# pse84 register map
Vendor: Infineon Technologies; Series: PSE84; File version: 1.0
CPU: CM33 r0p1, little endian, MPU, FPU, VTOR, 3 interrupt priority bits
Registers are 32-bit, read-write, reset 0x0 unless marked. A register's access mark holds for its fields unless they carry their own. Offsets are from the block's base; [hi:lo] are bit positions; lines under a group give offsets from that group; {n}, {i} and the like mark numbered series; 'fields as' and 'values as' point back to an identical list.

## ACTRLR — Autonomnous Controller
Base 0x42ED0000
0x00 CTRL — control register
  [31] ENABLED — - 0: LPPASS IP disabled - 1: LPPASS IP enabled This field functions as the Global Enable for the LPPASS IP. This field must be set to gain read/write access to any other register in the LPPASS memory map. During initial IP release from reset (i.e. during POR), the LPPASS IP (along with its switched internal power domain) is disabled. After setting this bit, the LPPASS internal switched domain is powered up. The user must then wait for PWR_STATUS.SW_OK to assert. At this point, the user has read/write access to all LPPASS memory map registers. Clearing this field (i.e. disabling the LPPASS) can lead to status only clearing, or status and configuration clearing (see CFG.DISABLE_MODE).
0x04 CMD_RUN — run command register
  [0] RUN — Autonomous Controller Run Command Firmware should only write to this field when STATUS=STOPPED or PAUSED. When firmware sets this field, the Autonomous Controller starts running at the State pointed to by CMD_STATE. Hardware clears this field when the Autonomous Controller acknowledges the run command. If this field is set while STATUS=RUNNING, the Autonomous Controller will not respond to the command (beyond clearing the field). This register is reset whenever the following occurs: 1. The Autonomous Controller is disabled (clearing CTRL.ENABLED) 2. The LPPASS is configured for HS mode (STATUS.MODE=0) and the chip leaves an Active Mode.
0x08 CMD_STATE — state override register
  [5:0] STATE — Autonomous Controller Command State This field indicates where which AC State (0-63) the AC will execute instructions from when it receives a RUN or SINGLE_STEP command. Hardware updates this field whenever the AC transitions from RUNNING to STOPPED or PAUSED. When STOPPED or PAUSED, firmware can overrwrite this field to force the AC to execute from a specific STATE when triggered by a subsequent RUN or SINGLE_STEP command. This field must never be written to if STATUS=RUNNING. This register is reset whenever the following occurs: 1. The Autonomous Controller is disabled (clearing CTRL.ENABLED) 2. The LPPASS is configured for HS mode (STATUS.MODE=0) and the chip leaves an Active Mode.
{0x10+4i} FW_TR[{i}] (i=0..3) — firmware trigger
  [0] FW_TR — Firmware Trigger This field is used as a firmware trigger for the Autonomous Controller. The Autonomous Controller can be programmed to respond to the firmware trigger by programming a state with a condtion (COND) TR_LPPASS_IN*. Additionally, writing to this field will force the Autonomus Controller to wake from sleep. Hardware clears this bit when the Autonomous Controller acknowledges the trigger. This register is reset whenever the following occurs: 1. The Autonomous Controller is disabled (clearing CTRL.ENABLED) 2. The LPPASS is configured for HS mode (STATUS.MODE=0) and the chip leaves an Active Mode.
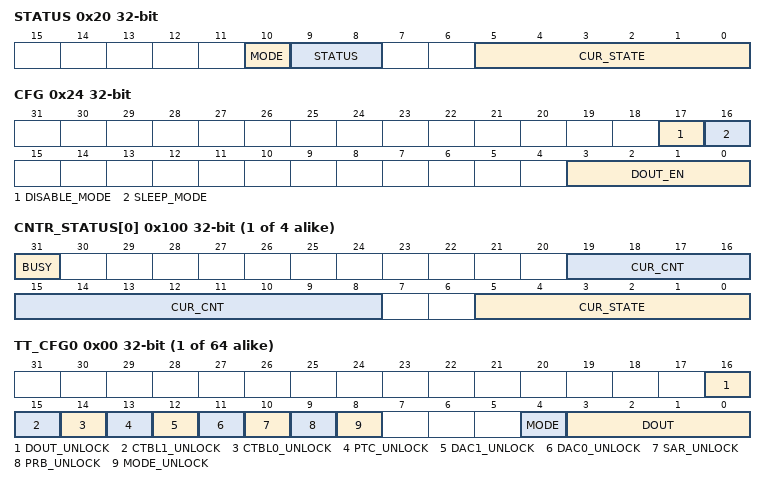
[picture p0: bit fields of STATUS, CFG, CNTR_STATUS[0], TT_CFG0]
0x20 STATUS ro
  [10] MODE — This field indicates the mode of the Autonomous Controller. The Autonmous Controller always resets to HS mode. This field is reset whenever the following occurs: 1. The Autonomous Controller is disabled (clearing CTRL.ENABLED) 2. The LPPASS is configured for HS mode (STATUS.MODE=0) and the chip leaves an Active Mode.
    0=HS (Autonomous Controller is in High Speed (HS) mode In this mode, the LPPASS IP is functional only in chip Active modes. The LPPASS IP is clocked from a peripheral source derived from clk_hf.); 1=LP (Autonomous Controller is Low Power (LP) mode In this mode, the LPPASS IP is functional in both chip Active and Deepsleep modes. The LPPASS IP is clocked from the internal LPOSC.)
  [9:8] STATUS — Autonomous Controller status
    0=STOPPED (Autonomous Controller is stopped); 1=RUNNING (Autonomous Controller is running); 2=PAUSED (Autonomous Controller is paused); 3=RSVD (N/A)
  [5:0] CUR_STATE — This register indicates the current state of the Autonomous Controller (valid values are 0-63).
0x24 CFG — config register (only accessible if CTRL.EN=0)
  [17] DISABLE_MODE — Autonomous Controller Disable Mode -0 : Keep the LPPASS switched digital supply powered when the AC is disabled ( i.e. CTRL.ENABLED=0). - 1: Power Down the LPPASS digital supply when AC is disabled. This has the following consequences to the LPPASS: 1. Digital leakage is reduced (i.e. all logic on the LPPASS switched supply is powered off). 2. All LPPASS configuration is lost (all registers are reset and SRAMs lose data).
  [16] SLEEP_MODE — Autonomous Controller Sleep Mode -0 : Keep the LPPASS switched digital supply powered when the AC is sleeping (i.e. AC state programmed to action (ACT)=WAIT_FOR, and condition (COND)=wakeup source). - 1: Power Down the LPPASS digital supply when AC is asleep (i.e. AC ACT=WAIT_FOR, AC_COND= wakeup source). This has the following consequences to the LPPASS: 1. Digital leakage is reduced (i.e. all logic on the LPPASS switched supply is powered off). 2. CTBLs, SAR FIRs, and the DACs loose all configuration (i.e. they must be re-programmed to be functional again). 3. The wakeup time is increased by 3us ( to account for the switched power domain coming up).
  [3:0] DOUT_EN — DOUT output enable. Bits in this field must be set prior to writing to TIMER_TABLE_STRUCT.TT_CF0_DOUT. -0 : DOUT[X] output disabled - 1: DOUT[X] output enabled
0x30 DEBUG_PAUSE — pause debug register
  [0] PAUSE — Pause Command Setting this field requests the Autonomous Controller (AC) to pause. This field is used for debug purposes only. The AC waits for the present state to complete before pausing. If the present state cannot complete (i.e. the ACT and COND are programmed improperly), the AC will not pause. This command must not be used when executing an AC sleep state (ACT=WAIT_FOR and COND=WAKE_*). When the AC is paused, all AC registerd conditions are cleared. Hardware clears this bit when the Autonomous Controller is paused. This command is ignored if STATUS.STATUS is PAUSED or STOP.
0x34 DEBUG_SINGLE_STEP — single step debug register
  [0] SINGLE_STEP — Single Step Command Setting this field requests the Autonomous Controller (AC) to execute the next AC state (pointed to by CMD_STATE.STATE) and pause after completing that state. This field is used for debug purposes only. If the state (pointed to by CMD_STATE.STATE) cannot complete (i.e. the ACT and COND are programmed improperly), the AC will not pause at the end of the single step command. This command must not be used when executing an AC sleep state (ACT=WAIT_FOR and COND=*_WAKE). When the AC is paused, all AC registerd conditions are cleared. Hardware clears this bit when the Autonomous Controller pauses after executing the single step command. This command is ignored if STATUS.STATUS is RUNNING.
0x38 PWR_STATUS ro — power status register
  [0] SW_OK — This field indicates the status of the LPPASS switched power domain. This status should be polled whenever CTRL.EN toggles from a 0 to 1. 0: switched domain is powered off. 1: switched domain is powered on.
{0x100+4i} CNTR_STATUS[{i}] (i=0..3) ro — Loop/Interval counter status register
  [31] BUSY — This field indicates if the counter is busy (i.e. count value is non-zero).
  [19:8] CUR_CNT — This field indicates the count value for the given counter.
  [5:0] CUR_STATE — This field indicates the assigned Autonomous Controller (AC) State of a counter. Valid numbers are 0-63.
{0x800+0x20*i} TTCFG[{i}] (i=0..63) group — Timer Table Structure (only accessible if CTRL.EN=0)
  0x00 TT_CFG0 — AC Table Configuration 0
    [16] DOUT_UNLOCK — DOUT Unlock 0: Lock: DOUT does NOT get updated 1: Unlock: DOUT does get updated
    [15] CTBL1_UNLOCK — See CTBL0_UNLOCK
    [14] CTBL0_UNLOCK — CTBL0 Unlock 0: Lock: CTBL0 fields: OPA1(0)_EN, OPA1(0)_GAIN, OPA1(0)_CFG do NOT get updated 1: Unlock: CTBL0 fields: OPA1(0)_EN, OPA1(0)_GAIN, OPA1(0)_CFG do get updated
    [13] PTC_UNLOCK — PTC Unlock 0: Lock: PTC fields: CMP1(0)_EN, CMP1(0)_CFG do NOT get updated 1: Unlock: PTC fields: CMP1(0)_EN, CMP1(0)_CFG do get updated
    [12] DAC1_UNLOCK — See DAC0_UNLOCK
    [11] DAC0_UNLOCK — DAC0 Unlock 0: Lock: DAC0 fields: EN does NOT get updated 1: Unlock: DAC0 fields: EN does get updated
    [10] SAR_UNLOCK — SAR Unlock 0: Lock: SAR fields: EN does NOT get updated 1: Unlock: SAR fields: EN does get updated
    [9] PRB_UNLOCK — PRB Unlock 0: Lock: PRB fields: VREF1(0)_VAL, VREF1(0)_FW_MODE do NOT get updated 1: Unlock: PRB fields: VREF1(0)_VAL, VREF1(0)_FW_MODE do get updated
    [8] MODE_UNLOCK — Mode Unlock 0: Lock: MODE does NOT get updated 1: Unlock: MODE does get updated
    [4] MODE — LPPASS Operating Mode 0: High Speed (HS) Operation - The PASS is clocked from CLK_HF directly (nominally 80MHz) and is only functional in chip Active mode (i.e. the IP is reset in chip Deepsleep and Hibernate) 1: Low Power (LP) Operation - The PASS is clocked from CLK_LPOSC (4MHz) and is functional in chip Active and Deepsleep mode (i.e. the IP is only reset in Hibernate)
    [3:0] DOUT — LPPASS data out generation (the corresponding bit in CFG.DOUT_EN must be set when using this field) The data out bus is driven directly to the GPIO HSIO interface. The HSIO interface must be programmed properly for the DOUT bus to be observed on the GPIO pins.
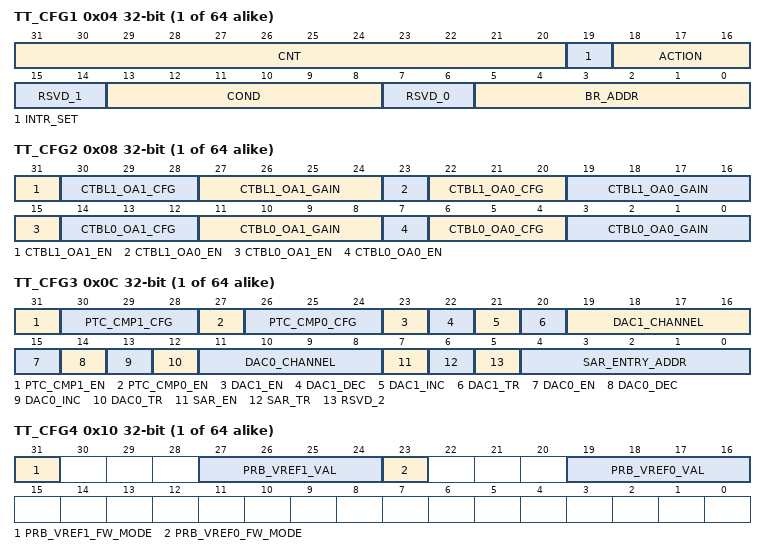
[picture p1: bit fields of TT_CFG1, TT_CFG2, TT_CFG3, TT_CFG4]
  0x04 TT_CFG1 reset not defined — AC Table Configuration 1
    [31:20] CNT — This field is used to set the timer/counter values for either interval and loop counts. The actual count is CNT+1. Therefore, the range is 1 to 4096. The value of 1 is degenerate. This field is only valid if the action (ACT) is set to WAIT_FOR, or BRANCH_IF_* and the condition (COND) is set to CNT_DONE. If ACT is set to WAIT_FOR, the counter is first loaded with CNT+1 and is subsequently decremented every clock cycle (clock set by MODE). On terminal count, the CNT_DONE trigger is asserted. If ACT is set to BRANCH_IF_*, the counter is first checked if it is busy (count value is nonzero). If busy, the counter is decremented. If not busy, the counter is loaded with CNT+1. On terminal count, the CNT_DONE trigger is asserted.
    [19] INTR_SET — AC Interrupt Set This field is used for setting the Autonomous Controller Interrupt and/or trigger. When set in a particular state, the AC generates a single cycle pulse to the interrupt logic. The AC interrupt or AC trigger must be unmasked for this field to generate an interrupt/trigger. If ACTION=WAIT_FOR, the signle cycle pulse is generated after the COND occurs, otherwise the single cycle pulse is sent immediately upon entering the state where the field is set.
    [18:16] ACTION — Autonomous Controller Action
      0=STOP (Stop the autonomous controller); 1=NEXT (Proceed to the next state); 2=WAIT_FOR (Wait for the associated COND to occur before moving to the next state If COND=FALSE, stay in the present state indefinitely. If COND=TRUE, move to the next state.); 3=BRANCH_IF_TRUE (Check if COND has occurred, If it has, take the indicated branch (BR ADDR), if not, proceed to the next state. If COND=FALSE, proceed to the next state. If COND=TRUE, take the indicated branch (BR_ADDR).); 4=BRANCH_IF_FALSE (Check if COND has occurred, If it has proceed to the next state, if not, take the indicated branch (BR ADDR) If COND=FALSE, take the indicated branch (BR_ADDR). If COND=TRUE, proceed to the next state.); 5=BRANCH_IF_TRUE_CLR (Check if COND has occurred, If it has, take the indicated branch (BR ADDR), if not, proceed to the next state.); 6=BRANCH_IF_FALSE_CLR (Check if COND has occurred, If it has proceed to the next state, if not, take the indicated branch (BR ADDR)); 7=RSVD0 (N/A)
    [15:14] RSVD_1
    [13:8] COND — Autonomous Controller Condition
      0=False (Hardcoded FALSE value); 1=True (Hardcoded TRUE value); 2=BLOCK_READY (Enabled block(s) are ready for use.); 3=CNT_DONE (if the ACTION is WAIT_FOR - this is an interval timer. If the ACTION is BRANCH IF - this is a loop counter.); 4=SAR_DONE (SAR Sequencer Done); 5=SAR_EOS (SAR Sequencer EOS); {v}=SAR_RANGE{v-6} (SAR Range {v-6} detection) (v=6..9); 10=SAR_BUSY (SAR BUSY detection This status is set whenever the SAR is running a scan. This status is transparent from the SAR sequencer (i.e. the status is not sticky).); 11=SAR_FIR0_DONE (SAR FIR0 Done detection); 12=SAR_FIR1_DONE (SAR FIR1 Done detection); 13=SAR_FIFO_DONE; 14=SAR_FIR0_FIFO_DONE (SAR FIR0 FIFO Done detection); 15=SAR_FIR1_FIFO_DONE (SAR FIR1 FIFO Done detection); 16=PTC_STROBE0 (PTC Post Processor 0 Strobe); 17=PTC_STROBE1 (PTC Post Processor 1 Strobe); 18=PTC_CMP0 (PTC COMP0 output); 19=PTC_CMP1 (PTC COMP1 output); 20=PTC_RANGE0 (PTC Post Processor 0 Range output); 21=PTC_RANGE1 (PTC Post Processor 1 Range output); 22=CTBL0_CMP0 (CTBL0 COMP0 output); 23=CTBL0_CMP1 (CTBL0 COMP1 output); 24=CTBL1_CMP0 (CTBL1 COMP0 output); 25=CTBL1_CMP1 (CTBL1 COMP1 output); {v}=RSVD{v-26} (N/A) (v=26..31); 32=CHIP_ACTIVE_MODE (Chip Active Mode Status This status is set whenever the system is operating in Active Mode (this includes all Low Power active modes)); 33=CHIP_DEEPSLEEP_MODE (Chip Deepsleep Mode Status This status is set whenever the system is operating in Deepsleep Mode (this includes all RAM power modes in Deepsleep)); {v}=TR_LPPASS_IN{v-34} (External trigger 0 (or the FW trigger {v-34})) (v=34..37); 38=TR_LPPASS_IN_WAKE (External Trigger Wakeup Source); 39=TIMER_DONE_WAKE (Timer Wakeup Source); 40=CTBL0_CMP0_WAKE (CTBL0 comparator 0 wakeup); 41=CTBL0_CMP1_WAKE (CTBL0 comparator 1 wakeup); 42=CTBL1_CMP0_WAKE (CTBL1 comparator 0 wakeup); 43=CTBL1_CMP1_WAKE (CTBL1 comparator 1 wakeup); 44=PTC_CMP0_WAKE (PTC comparator 0 wakeup); 45=PTC_CMP1_WAKE (PTC comparator 1 wakeup); 46=FIFO_LEVEL0 (FIFO Level 0 trigger This status is set whenever FIFO0 level condition has been met (FIFO_LEVEL0.LEVEL). This status is transparent from the FIFO (i.e. the status is not sticky).); {v}=FIFO_LEVEL{v-46} (FIFO Level {v-46} trigger) (v=47..53); 54=DAC0_RANGE0 (DAC0 Range 0 detection); 55=DAC0_RANGE1 (DAC0 Range 1 detection); 56=DAC0_RANGE2 (DAC0 Range 2 detection); 57=DAC0_EPOCH (DAC0 End of Waveform event); 58=DAC0_STROBE; 59=DAC1_RANGE0 (DAC1 Range 0 detection); 60=DAC1_RANGE1 (DAC1 Range 1 detection); 61=DAC1_RANGE2 (DAC1 Range 2 detection); 62=DAC1_EPOCH (DAC1 End of Waveform event); 63=DAC1_STROBE
    [7:6] RSVD_0
    [5:0] BR_ADDR — absolute address of the branch if taken (0-63 possible). This field in only used if the AC action (ACT) is set to BRANCH_IF_* and the condtion (COND) is met.
  0x08 TT_CFG2 reset not defined — AC Table Configuration 2
    [31] CTBL1_OA1_EN — CTBL1 Opamp1 enable This field is only used by the Autonomous Controller if CTBL1_UNLOCK is set. Otherwise, the field is ignored.
      0=DISABLED (Disabled CTBL1 Opamp1 is powered down, comparator logic is reset and all CTBL1 OA1 AC conditions are cleared. CTBL1 configuration is retained.); 1=ENABLED (Enabled CTBL1 Opamp1 is powered and all logic is enabled and clocked.)
    [30:28] CTBL1_OA1_CFG — See CTBL0_OA0_CFG
    [27:24] CTBL1_OA1_GAIN — See CTBL0_OA0_GAIN
    [23] CTBL1_OA0_EN — See CTBL0_OA0_EN
    [22:20] CTBL1_OA0_CFG — See CTBL0_OA0_CFG
    [19:16] CTBL1_OA0_GAIN — See CTBL0_OA0_GAIN
    [15] CTBL0_OA1_EN — See CTBL0_OA0_EN
    [14:12] CTBL0_OA1_CFG — CTBL0 Opamp1 Mux Configuration This field determines the state of all input and reference muxes to the Opamp along with the output driver (i.e. if the oamp drives internal loads only or internal/external loads). This field is only used by the Autonomous Controller if CTBL0_UNLOCK is set. Otherwise, the field is ignored.
      {v}=CFG_{v} (Configuration {v} Mux settings determined by CTBL0_DYN_CFG_STRUCT_Regs{v}) (v=0..7)
    [11:8] CTBL0_OA1_GAIN — CTBL0 Opamp1 gain control. This field affects the value of the input (Rin) and feedback (Rfb) resistors. This field is only used by the Autonomous Controller if CTBL0_UNLOCK is set. Otherwise, the field is ignored. This field is only valid if CTBL0_STA_CFG_Regs.CFG.OA1_TOPO= 1 (PGA), 2 (TIA), 4 (Differential Amplifier) For PGA and Differential Amplifier configuration, both input and feedback resistors are used. For TIA configuration, only the feedback resistor is used. For Differential Amplifier configurations, CTBL0_OA0_GAIN must equal CTBL0_OA1_GAIN
      0=Rin = 192k, Rfb = 0 Gain of 1.00; 1=1_42 (Rin = 135k, Rfb = 57k Non-Inverting PGA: Gain of 1.42 Inverting PGA: Gain of 0.42...); 2=2_00 (Rin = 96k, Rfb = 96k Non-Inverting PGA: Gain of 2.00 Inverting PGA: Gain of 1.00...); 3=2_78 (Rin = 69k, Rfb = 123k Non-Inverting PGA: Gain of 2.78 Inverting PGA: Gain of 1.78...); 4=4_00 (Rin = 48k, Rfb = 144k Non-Inverting PGA: Gain of 4.00 Inverting PGA: Gain of 3.00...); 5=5_82 (Rin = 33k, Rfb = 159k Non-Inverting PGA: Gain of 5.82 Inverting PGA: Gain of 4.82...); 6=8_00 (Rin = 24k, Rfb = 168k Non-Inverting PGA: Gain of 8.00 Inverting PGA: Gain of 7.00...); 7=10_67 (Rin = 18k, Rfb = 174k Non-Inverting PGA: Gain of 10.67 Inverting PGA: Gain of 9.67...); 8=16_00 (Rin = 12k, Rfb = 180k Non-Inverting PGA: Gain of 16.00 Inverting PGA: Gain of 15.00...); 9=21_33 (Rin = 9k, Rfb = 183k Non-Inverting PGA: Gain of 21.33 Inverting PGA: Gain of 20.33...); 10=32_00 (Rin = 6k, Rfb = 186k Non-Inverting PGA: Gain of 32.00 Inverting PGA: Gain of 31.00...); {v}=RSVD_{v-11} (N/A) (v=11..15)
    [7] CTBL0_OA0_EN — CTBL0 Opamp0 enable This field is only used by the Autonomous Controller if CTBL0_UNLOCK is set. Otherwise, the field is ignored.
      0=DISABLED (Disabled CTBL0 Opamp0 is powered down, comparator logic is reset and all CTBL0 OA0 AC conditions are cleared. CTBL0 configuration is retained.); 1=ENABLED (Enabled CTBL0 Opamp0 is powered and all logic is enabled and clocked.)
    [6:4] CTBL0_OA0_CFG — CTBL0 Opamp0 Mux Configuration This field determines the state of all input and reference muxes to the Opamp along with the output driver (i.e. if the oamp drives internal loads only or internal/external loads). This field is only used by the Autonomous Controller if CTBL0_UNLOCK is set. Otherwise, the field is ignored.
      values as CTBL0_OA1_CFG
    [3:0] CTBL0_OA0_GAIN — CTBL0 Opamp0 gain control. This field affects the value of the input (Rin) and feedback (Rfb) resistors. This field is only used by the Autonomous Controller if CTBL0_UNLOCK is set. Otherwise, the field is ignored. This field is only valid if CTBL0_STA_CFG_Regs.CFG.OA0_TOPO= 1 (PGA), 2 (TIA), 4 (Differential Amplifier) For PGA and Differential Amplifier configuration, both input and feedback resistors are used. For TIA configuration, only the feedback resistor is used. For Differential Amplifier configurations, CTBL0_OA0_GAIN must equal CTBL0_OA1_GAIN
      values as CTBL0_OA1_GAIN
  0x0C TT_CFG3 reset not defined — AC Table Configuration 3
    [31] PTC_CMP1_EN — See PTC_CMP0_EN
    [30:28] PTC_CMP1_CFG — See PTC_CMP0_CFG
    [27] PTC_CMP0_EN — PTC Comparator0 enable This field is only used by the Autonomous Controller if PTC_UNLOCK is set. Otherwise, the field is ignored.
      0=DISABLED (Disabled PTC Comparator 0 is powered down, Comparator 0 logic is reset, and Comparator 0 clock is gated. PTC_COMP0 AC condition is cleared. PTC_STROBE0 and PTC_RANGE0 are functional if PTC_COMP1_EN is set. Otherwise those conditions are cleared/disabled. PTC Comparator 0 configuration is retained.); 1=ENABLED (Enabled PTC Comparator 0 is powered and all logic is enabled and clocked.)
    [26:24] PTC_CMP0_CFG — PTC Comp0 Mux Configuration This field determines the state of all input muxes to the Comparator 0. This field is only used by the Autonomous Controller if PTC_UNLOCK is set. Otherwise, the field is ignored.
      {v}=CFG_{v} (Configuration {v} Mux settings determined by PTC_DYN_CFG_STRUCT_Regs{v}) (v=0..7)
    [23] DAC1_EN — See DAC0_EN
    [22] DAC1_DEC — See DAC0_DEC
    [21] DAC1_INC — See DAC0_INC
    [20] DAC1_TR — See DAC0_TR
    [19:16] DAC1_CHANNEL — See DAC0_CHANNEL
    [15] DAC0_EN — DAC0 enable This field is only used by the Autonomous Controller if DAC0_UNLOCK is set. Otherwise, the field is ignored.
      0=DISABLED (Disabled DAC0 is powered down, DAC0 logic is reset, DAC0 clocks are gated, and all DAC0 AC conditions are cleared. DAC0 configuration and waveform tables are retained.); 1=ENABLED (Enabled DAC0 is powered and all logic is enabled and clocked.)
    [14] DAC0_DEC — DAC0 Decrement When entering a state where this field is set, the AC generates a single cycle pulse (decrement) to the DAC0 logic. DAC_INC and DAC_DEC CANNOT be simultaneously set in a given state (doing so will cause DAC_DEC to be ignored by the DAC0 logic). This field is only used by the DAC0 logic if the DAC0_CHANNEL field is set to 0-14 (Hardware channels) and DAC0.DAC_STA_CFG.CHAN_CFG.MODE = ADDR or DATA. If DAC0.DAC_STA_CFG.CHAN_CFG.MODE=ADDR, the DAC0 logic decrements the DAC address (Amount set by DAC0.DAC_STA_CFG.CHAN_CFG.STEP_SIZE_EN and STEP_SIZE_SEL) If DAC0.DAC_STA_CFG.CHAN_CFG.MODE=DATA, the DAC0 logic decrements the DAC Value (Amount set by CHAN_CFG.STEP_SIZE_EN and STEP_SIZE_SEL)
    [13] DAC0_INC — DAC0 Increment When entering a state where this field is set, the AC generates a single cycle pulse (increment) to the DAC0 logic. DAC_INC and DAC_DEC CANNOT be simultaneously set in a given state (doing so will cause DAC_DEC to be ignored by the DAC0 logic). This field is only used by the DAC0 logic if the DAC0_CHANNEL field is set to 0-14 (Hardware channels) and DAC0.DAC_STA_CFG.CHAN_CFG.MODE = ADDR or DATA. If DAC0.DAC_STA_CFG.CHAN_CFG.MODE=ADDR, the DAC0 logic increments the DAC address (Amount set by DAC0.DAC_STA_CFG.CHAN_CFG.STEP_SIZE_EN and STEP_SIZE_SEL) If DAC0.DAC_STA_CFG.CHAN_CFG.MODE=DATA, the DAC0 logic increments the DAC Value (Amount set by CHAN_CFG.STEP_SIZE_EN and STEP_SIZE_SEL)
    [12] DAC0_TR — DAC0 Trigger This field initiates DAC operation per the DAC0_CHANNEL selection. When entering a state where this field is set, the AC generates a single cycle pulse (trigger) to the DAC0 logic. This field is ignored unless: the DAC has been enabled in a prior state (DAC0_EN=1) and is ready (i.e. the AC has waited for BLOCK_READY in the same state where DAC0 was enabled). The DAC does NOT need to be disabled when switching channels.
    [11:8] DAC0_CHANNEL — DAC0 Channel select This field is pointer to the active DAC channel. Valid values are 0-15. This field is ignored unless the following conditions are guaranteed: 1. The DAC is triggered (DAC0_TR=1). 2. The DAC has been enabled in a prior state (DAC0_EN=1) and is ready (i.e. the AC has waited for BLOCK_READY in the same state where DAC0 was enabled).
      {v}=CHANNEL_{v} (v=0..14); 15=FW_CHANNEL
    [7] SAR_EN — SAR enable This field is only used by the Autonomous Controller if SAR_UNLOCK is set. Otherwise, the field is ignored.
      0=DISABLED; 1=ENABLED (Enabled SAR is powered and all SAR (FIR) logic is enabled and clocked.)
    [6] SAR_TR — SAR Trigger (initiate SAR operation at sequencer address pointed to by SAR_ENTRY_ADDR) When entering a state where this field is set, the AC generates a single cycle pulse (trigger) to the SAR sequencer. This trigger is ignored by the SAR sequencer unless ALL of the following conditions are guaranteed: 1. The SAR has been enabled in a prior state (SAR_EN=1) and is ready (i.e. the AC has waited for BLOCK_READY in the same state where the SAR was enabled). 2. The SAR is idle (SAR.SAR_STA_CFG.STATUS.BUSY=0).
    [5] RSVD_2
    [4:0] SAR_ENTRY_ADDR — SAR Timer Table Entry State This field is a pointer to the entry address of the SAR sequencer state table. If ACTRLR.STATUS.MODE=0, this field points to the High Speed state table (SEQ.HS.DATA) If ACTRLR.STATUS.MODE=1, this field points to the Low Power state table (SEQ.LP.DATA) Valid values are 0-31. This field is ignored unless the following conditions are guaranteed: 1. The SAR is triggered (SAR_TR=1). 2. The SAR has been enabled in a prior state (SAR_EN=1) and is ready (i.e. the AC has waited for BLOCK_READY in the same state where the SAR was enabled). 3. The SAR is idle (SAR.SAR_STA_CFG.STATUS.BUSY=0). This field is pointer to the entry address of the SAR sequencer state table. If ACTRLR.STATUS.MODE=0, this field points to the High Speed state table (SEQ.HS.DATA) If ACTRLR.STATUS.MODE=1, this field points to the Low Power state table (SEQ.LP.DATA)
  0x10 TT_CFG4 — AC Table Configuration 4
    [31] PRB_VREF1_FW_MODE — See PRB_VREF0_FW_MODE
    [27:24] PRB_VREF1_VAL — See PRB_VREF0_VAL
    [23] PRB_VREF0_FW_MODE — PRB VREF0 Firmware Mode This field is only used by the Autonomous Controller if PRB_UNLOCK is set. Otherwise, the field is ignored. Prior to writing to this field, VREF0 must be enabled (PRB.VREF_CTRL0.EN=1).
      0=DISABLED (Disabled (PRB output determined by TT.CFG4.PRB_VREF0_VAL)); 1=ENABLED (Enabled (PRB output determined by PRB.PRB_VREF_CTRL0.VAL))
    [19:16] PRB_VREF0_VAL — TAP location for PRB VREF0. This field is only used by the Autonomous Controller if PRB_UNLOCK is set. Otherwise, the field is ignored. Prior the writing to this field, the following must be met: 1. PRB.VREF_CTRL0.EN=1 (VREF0 is enabled) 2. PRB_VREF0_FW_MODE = 0 (VREF0 is configured for Autonomous Controller control) The field is reset only when disabling the AC.
      0=TAP_0 (VREF0 = 0.06*PRB.VREF_CTRL.CFG); 1=TAP_1 (VREF0 = 0.13*PRB.VREF_CTRL.CFG); 2=TAP_2 (VREF0 = 0.19*PRB.VREF_CTRL.CFG); 3=TAP_3 (VREF0 = 0.25*PRB.VREF_CTRL.CFG); 4=TAP_4 (VREF0 = 0.31*PRB.VREF_CTRL.CFG); 5=TAP_5 (VREF0 = 0.38*PRB.VREF_CTRL.CFG); 6=TAP_6 (VREF0 = 0.44*PRB.VREF_CTRL.CFG); 7=TAP_7 (VREF0 = 0.50*PRB.VREF_CTRL.CFG); 8=TAP_8 (VREF0 = 0.56*PRB.VREF_CTRL.CFG); 9=TAP_9 (VREF0 = 0.63*PRB.VREF_CTRL.CFG); 10=TAP_10 (VREF0 = 0.69*PRB.VREF_CTRL.CFG); 11=TAP_11 (VREF0 = 0.75*PRB.VREF_CTRL.CFG); 12=TAP_12 (VREF0 = 0.81*PRB.VREF_CTRL.CFG); 13=TAP_13 (VREF0 = 0.88*PRB.VREF_CTRL.CFG); 14=TAP_14 (VREF0 = 0.94*PRB.VREF_CTRL.CFG); 15=TAP_15 (VREF0 = 1.00*PRB.VREF_CTRL.CFG)
